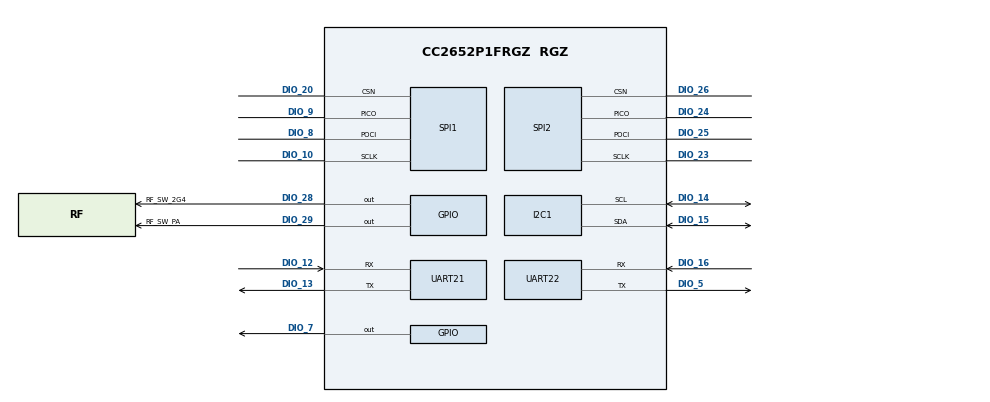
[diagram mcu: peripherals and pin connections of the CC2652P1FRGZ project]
/**
 * SCK-2400 Mini V3 -- CC2652P1FRGZ, custom board (no LaunchPad).
 * Retargeted from sck2400.syscfg 10/20/26. Pin assignments taken from the
 * V3 board copper (v3f, as ordered), not from LaunchPad boosterpack names.
 *
 * Open this in SysConfig once and let it re-save: it will rewrite the
 * @cliArgs/@versions header and add $suggestSolution lines for DMA etc.
 *
 * @cliArgs --device "CC2652P1FRGZ" --part "Default" --package "RGZ" --rtos "tirtos7" --product "simplelink_cc13xx_cc26xx_sdk@8.32.00.07"
 * @versions {"tool":"1.21.1+3772"}
 *
 * V3 DIO map (package pin -> DIO -> function -> board)
 *   10 DIO_5   DEBUG_UART TX      J3.5
 *   11 DIO_6   Bootloader backdoor J4.5, R40 pull-up (CCFG below)
 *   12 DIO_7   Status LED         R3 -> D1
 *   14 DIO_8   SPI0 POCI          U3.2 (flash DO)
 *   15 DIO_9   SPI0 PICO          U3.5 (flash DI)
 *   16 DIO_10  SPI0 SCLK          U3.6
 *   18 DIO_12  PAYLOAD_UART RX    J4.2  (also ROM bootloader RX)
 *   19 DIO_13  PAYLOAD_UART TX    J4.3  (also ROM bootloader TX)
 *   20 DIO_14  I2C SCL            J7.4, R6 4.7k
 *   21 DIO_15  I2C SDA            J7.3, R5 4.7k
 *   26 DIO_16  DEBUG_UART RX      J3.4  (shared with J2.6 TDO)
 *   27 DIO_17  (free)             J2.8 TDI only
 *   30 DIO_20  SPI0 CS            U3.1
 *   36 DIO_23  SPI1 SCLK          J5
 *   37 DIO_24  SPI1 PICO          J5
 *   38 DIO_25  SPI1 POCI          J5
 *   39 DIO_26  SPI1 CS            J5
 *   41 DIO_28  RF_SW_2G4          U6.6 (V2, standard path)
 *   42 DIO_29  RF_SW_PA           U6.4 (V1, 20 dBm PA path)
 *   Unused/no copper: DIO_11, 18, 19, 21, 22, 27, 30
 */

/**
 * Import the modules used in this configuration.
 */
const CCFG        = scripting.addModule("/ti/devices/CCFG");
const custom      = scripting.addModule("/ti/devices/radioconfig/custom");
const rfdesign    = scripting.addModule("/ti/devices/radioconfig/rfdesign");
const GPIO        = scripting.addModule("/ti/drivers/GPIO");
const GPIO1       = GPIO.addInstance();
const GPIO2       = GPIO.addInstance();
const GPIO3       = GPIO.addInstance();
const I2C         = scripting.addModule("/ti/drivers/I2C", {}, false);
const I2C1        = I2C.addInstance();
const NVS         = scripting.addModule("/ti/drivers/NVS", {}, false);
const NVS1        = NVS.addInstance();
const Power       = scripting.addModule("/ti/drivers/Power");
const RF          = scripting.addModule("/ti/drivers/RF", {}, false);
const SPI         = scripting.addModule("/ti/drivers/SPI", {}, false);
const SPI1        = SPI.addInstance();
const SPI2        = SPI.addInstance();
const UART2       = scripting.addModule("/ti/drivers/UART2", {}, false);
const UART21      = UART2.addInstance();
const UART22      = UART2.addInstance();
const Watchdog    = scripting.addModule("/ti/drivers/Watchdog", {}, false);
const Watchdog1   = Watchdog.addInstance();
const Settings    = scripting.addModule("/ti/posix/tirtos/Settings");
const BIOS        = scripting.addModule("/ti/sysbios/BIOS");
const Clock       = scripting.addModule("/ti/sysbios/knl/Clock");
const Event       = scripting.addModule("/ti/sysbios/knl/Event");
const Idle        = scripting.addModule("/ti/sysbios/knl/Idle", {}, false);
const Idle2       = Idle.addInstance();
const Mailbox     = scripting.addModule("/ti/sysbios/knl/Mailbox");
const Error       = scripting.addModule("/ti/sysbios/runtime/Error");
const SysCallback = scripting.addModule("/ti/sysbios/runtime/SysCallback");
const Timestamp   = scripting.addModule("/ti/sysbios/runtime/Timestamp");

/**
 * Write custom configuration values to the imported modules.
 */

/* Bootloader backdoor: DIO6 (pkg pin 11) -> J4.5 "BackDoor", R40 pull-up.
 * Hold J4.5 low through reset to enter the ROM UART bootloader on
 * DIO12/DIO13 (J4.2/J4.3). Unchanged from the LaunchPad build. */
CCFG.enableBootloader         = true;
CCFG.levelBootloaderBackdoor  = "Active low";
CCFG.enableBootloaderBackdoor = true;
CCFG.dioBootloaderBackdoor    = 6;
CCFG.ccfgTemplate.$name       = "ti_devices_CCFG_CCFGCC26XXTemplate0";

/* PHY unchanged: 2-GFSK 250 kbps at 2440 MHz, both PA tables exported. */
custom.prop2                                             = ["2gfsk250kbps"];
custom.radioConfig2gfsk250kbps.$name                     = "ti_devices_radioconfig_settings_prop0";
custom.radioConfig2gfsk250kbps.codeExportConfig.$name    = "ti_devices_radioconfig_code_export_param0";
custom.radioConfig2gfsk250kbps.codeExportConfig.paExport = "dual";

/* V3 copies the -2 2.4 GHz front end (20 dBm PA from VDDS). TI's guidance
 * for a CC2652P on this front end is to select LAUNCHXL-CC1352P-2 here. */
rfdesign.rfDesign = "LAUNCHXL-CC1352P-2";

/* RF switch lines -- driven by radio.c, not the SysConfig switch callback.
 * Initial states give a valid SKYA21001 state from GPIO_init() onward:
 * standard path selected, PA path deselected (never both high). */
GPIO1.$name              = "RF_SW_2G4";
GPIO1.mode               = "Output";
GPIO1.initialOutputState = "High";
GPIO1.gpioPin.$assign    = "DIO_28";

GPIO2.$name              = "RF_SW_PA";
GPIO2.mode               = "Output";
GPIO2.initialOutputState = "Low";
GPIO2.gpioPin.$assign    = "DIO_29";

GPIO3.$name              = "CONFIG_GPIO_GLED";
GPIO3.mode               = "Output";
GPIO3.gpioPin.$assign    = "DIO_7";

/* I2C controller on J7 (Qwiic order: 1 GND, 2 3V3, 3 SDA, 4 SCL).
 * External 4.7k pull-ups R5/R6 -- no internal pulls needed.
 * Firmware does not open it yet (I2C_init()/I2C_open() come later). */
I2C1.$name              = "CONFIG_I2C_0";
I2C1.i2c.sclPin.$assign = "DIO_14";
I2C1.i2c.sdaPin.$assign = "DIO_15";

NVS1.$name                    = "CONFIG_NVSINTERNAL";
NVS1.internalFlash.$name      = "ti_drivers_nvs_NVSCC26XX0";
NVS1.internalFlash.regionBase = 0x52000;

/* SPI0 (SSI0): external flash U3, MX25V8035FZUI. Same DIOs as LaunchPad. */
SPI1.$name               = "CONFIG_SPI_0";
SPI1.mode                = "Four Pin CS Active Low";
SPI1.spi.$assign         = "SSI0";
SPI1.spi.sclkPin.$assign = "DIO_10";
SPI1.spi.pociPin.$assign = "DIO_8";
SPI1.spi.picoPin.$assign = "DIO_9";
SPI1.spi.csnPin.$assign  = "DIO_20";

/* SPI1 (SSI1): J5 expansion header. */
SPI2.$name               = "CONFIG_SPI_1";
SPI2.mode                = "Four Pin CS Active Low";
SPI2.spi.$assign         = "SSI1";
SPI2.spi.sclkPin.$assign = "DIO_23";
SPI2.spi.picoPin.$assign = "DIO_24";
SPI2.spi.pociPin.$assign = "DIO_25";
SPI2.spi.csnPin.$assign  = "DIO_26";

/* PAYLOAD_UART on J4 (silk "UART1"). Same DIOs as the ROM bootloader. */
UART21.$name              = "PAYLOAD_UART";
UART21.enableNonblocking  = false;
UART21.uart.txPin.$assign = "DIO_13";
UART21.uart.rxPin.$assign = "DIO_12";

/* DEBUG_UART on J3 (silk "UART0"). */
UART22.$name              = "DEBUG_UART";
UART22.uart.txPin.$assign = "DIO_5";
UART22.uart.rxPin.$assign = "DIO_16";

Watchdog1.$name  = "CONFIG_WATCHDOG_0";
Watchdog1.period = 30000;

BIOS.assertsEnabled = false;
BIOS.heapBaseAddr   = "__primary_heap_start__";
BIOS.heapEndAddr    = "__primary_heap_end__";

const Timer = scripting.addModule("/ti/sysbios/family/arm/cc26xx/Timer", {}, false);

Idle2.$name   = "powerIdle";
Idle2.idleFxn = "Power_idleFunc";

const Semaphore            = scripting.addModule("/ti/sysbios/knl/Semaphore", {}, false);
Semaphore.supportsPriority = false;

const Swi         = scripting.addModule("/ti/sysbios/knl/Swi", {}, false);
Swi.numPriorities = 6;

const Task             = scripting.addModule("/ti/sysbios/knl/Task", {}, false);
Task.checkStackFlag    = false;
Task.defaultStackSize  = 512;
Task.idleTaskStackSize = 512;
Task.numPriorities     = 6;

Error.policy       = "Error_SPIN";
Error.printDetails = false;

const System           = scripting.addModule("/ti/sysbios/runtime/System", {}, false);
System.abortFxn        = "System_abortSpin";
System.exitFxn         = "System_exitSpin";
System.extendedFormats = "%f";
System.supportModule   = "SysCallback";
